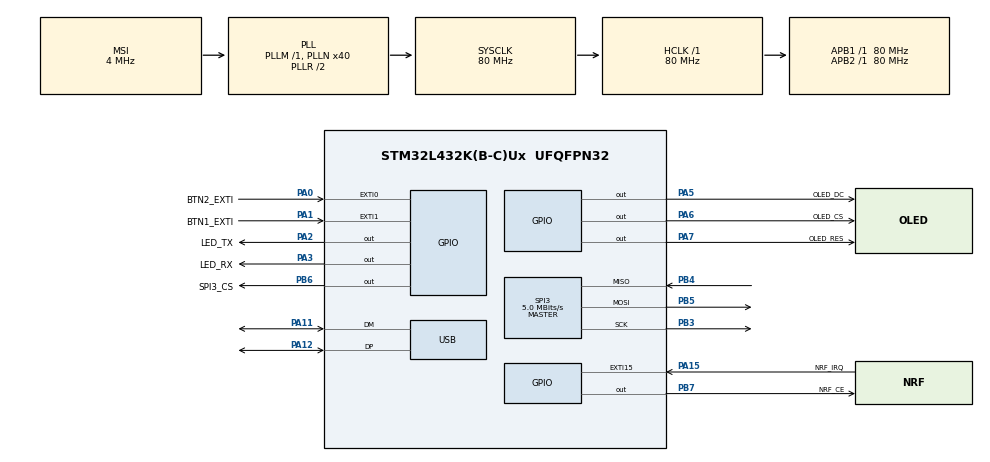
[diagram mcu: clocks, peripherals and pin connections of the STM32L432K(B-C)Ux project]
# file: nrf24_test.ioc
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Mcu.Family=STM32L4
Mcu.Name=STM32L432K(B-C)Ux
Mcu.Package=UFQFPN32
NVIC.EXTI15_10_IRQn=true\:0\:0\:false\:false\:true\:true\:true\:true
NVIC.PriorityGroup=NVIC_PRIORITYGROUP_4
NVIC.SPI3_IRQn=true\:0\:0\:false\:false\:true\:true\:true\:true
PA0.GPIO_Label=BTN2_EXTI
PA0.Signal=GPXTI0
PA1.GPIO_Label=BTN1_EXTI
PA1.Signal=GPXTI1
PA11.Mode=Device
PA11.Signal=USB_DM
PA12.Mode=Device
PA12.Signal=USB_DP
PA13\ (JTMS-SWDIO).Mode=Serial_Wire
PA13\ (JTMS-SWDIO).Signal=SYS_JTMS-SWDIO
PA14\ (JTCK-SWCLK).Mode=Serial_Wire
PA14\ (JTCK-SWCLK).Signal=SYS_JTCK-SWCLK
PA15\ (JTDI).GPIO_Label=NRF_IRQ
PA15\ (JTDI).Signal=GPXTI15
PA2.GPIO_Label=LED_TX
PA2.Signal=GPIO_Output
PA3.GPIO_Label=LED_RX
PA3.Signal=GPIO_Output
PA5.GPIO_Label=OLED_DC
PA5.Signal=GPIO_Output
PA6.GPIO_Label=OLED_CS
PA6.Signal=GPIO_Output
PA7.GPIO_Label=OLED_RES
PA7.Signal=GPIO_Output
PB3\ (JTDO-TRACESWO).Mode=Full_Duplex_Master
PB3\ (JTDO-TRACESWO).Signal=SPI3_SCK
PB4\ (NJTRST).Mode=Full_Duplex_Master
PB4\ (NJTRST).Signal=SPI3_MISO
PB5.Mode=Full_Duplex_Master
PB5.Signal=SPI3_MOSI
PB6.GPIO_Label=SPI3_CS
PB6.PinState=GPIO_PIN_SET
PB6.Signal=GPIO_Output
PB7.GPIO_Label=NRF_CE
PB7.Signal=GPIO_Output
ProjectManager.HeapSize=0x200
ProjectManager.StackSize=0x400
ProjectManager.TargetToolchain=STM32CubeIDE
RCC.ADCFreq_Value=48000000
RCC.AHBFreq_Value=80000000
RCC.APB1Freq_Value=80000000
RCC.APB1TimFreq_Value=80000000
RCC.APB2Freq_Value=80000000
RCC.APB2TimFreq_Value=80000000
RCC.CortexFreq_Value=80000000
RCC.HCLKFreq_Value=80000000
RCC.HSE_VALUE=8000000
RCC.HSI48_VALUE=48000000
RCC.HSI_VALUE=16000000
RCC.LSE_VALUE=32768
RCC.MSI_VALUE=4000000
RCC.PLLN=40
RCC.PLLSAI1N=24
RCC.SYSCLKFreq_VALUE=80000000
RCC.SYSCLKSource=RCC_SYSCLKSOURCE_PLLCLK
RCC.USBFreq_Value=48000000
RCC.VCOOutputFreq_Value=160000000
SPI3.BaudRatePrescaler=SPI_BAUDRATEPRESCALER_16
SPI3.CalculateBaudRate=5.0 MBits/s
SPI3.DataSize=SPI_DATASIZE_8BIT
SPI3.Direction=SPI_DIRECTION_2LINES
SPI3.Mode=SPI_MODE_MASTER
SPI3.VirtualType=VM_MASTER
VP_RCC_USB.Mode=CRS SYNC Source USB
board=custom

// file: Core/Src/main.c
/* USER CODE BEGIN Header */
/**
  ******************************************************************************
  * @file           : main.c
  * @brief          : Main program body
  ******************************************************************************
  * @attention
  *
  * Copyright (c) 2025 STMicroelectronics.
  * All rights reserved.
  *
  * This software is licensed under terms that can be found in the LICENSE file
  * in the root directory of this software component.
  * If no LICENSE file comes with this software, it is provided AS-IS.
  *
  ******************************************************************************
  */
/* USER CODE END Header */
#include "main.h"

/* USER CODE BEGIN PD */
#define NRF24_CMD_R_REGISTER 	0x00U
#define NRF24_REG_STATUS 		0x07U

/* USER CODE END PD */

SPI_HandleTypeDef hspi3;

PCD_HandleTypeDef hpcd_USB_FS;

void SystemClock_Config(void);
static void MX_GPIO_Init(void);
static void MX_SPI3_Init(void);
static void MX_USB_PCD_Init(void);
/* USER CODE BEGIN PFP */
uint8_t nrf24_read_register(uint8_t reg);
/* USER CODE END PFP */

int main(void)
{

  /* MCU Configuration--------------------------------------------------------*/

  /* Reset of all peripherals, Initializes the Flash interface and the Systick. */
  HAL_Init();

  /* Configure the system clock */
  SystemClock_Config();

  /* Initialize all configured peripherals */
  MX_GPIO_Init();
  MX_SPI3_Init();
  MX_USB_PCD_Init();
  /* USER CODE BEGIN 2 */
  uint8_t status = nrf24_read_register(NRF24_REG_STATUS);
  if (status != 0xFF && status != 0x00){
	  //succes
	  HAL_GPIO_WritePin(LED_RX_GPIO_Port, LED_RX_Pin, GPIO_PIN_SET);
	  HAL_GPIO_WritePin(LED_TX_GPIO_Port, LED_TX_Pin, GPIO_PIN_SET);
  }

  /* USER CODE END 2 */

  /* Infinite loop */
  while (1)
  {

  }
}

void SystemClock_Config(void)
{
  RCC_OscInitTypeDef RCC_OscInitStruct = {0};
  RCC_ClkInitTypeDef RCC_ClkInitStruct = {0};
  RCC_CRSInitTypeDef RCC_CRSInitStruct = {0};

  /** Configure the main internal regulator output voltage
  */
  if (HAL_PWREx_ControlVoltageScaling(PWR_REGULATOR_VOLTAGE_SCALE1) != HAL_OK)
  {
    Error_Handler();
  }

  /** Initializes the RCC Oscillators according to the specified parameters
  * in the RCC_OscInitTypeDef structure.
  */
  RCC_OscInitStruct.OscillatorType = RCC_OSCILLATORTYPE_MSI;
  RCC_OscInitStruct.MSIState = RCC_MSI_ON;
  RCC_OscInitStruct.MSICalibrationValue = 0;
  RCC_OscInitStruct.MSIClockRange = RCC_MSIRANGE_6;
  RCC_OscInitStruct.PLL.PLLState = RCC_PLL_ON;
  RCC_OscInitStruct.PLL.PLLSource = RCC_PLLSOURCE_MSI;
  RCC_OscInitStruct.PLL.PLLM = 1;
  RCC_OscInitStruct.PLL.PLLN = 40;
  RCC_OscInitStruct.PLL.PLLP = RCC_PLLP_DIV7;
  RCC_OscInitStruct.PLL.PLLQ = RCC_PLLQ_DIV2;
  RCC_OscInitStruct.PLL.PLLR = RCC_PLLR_DIV2;
  if (HAL_RCC_OscConfig(&RCC_OscInitStruct) != HAL_OK)
  {
    Error_Handler();
  }

  /** Initializes the CPU, AHB and APB buses clocks
  */
  RCC_ClkInitStruct.ClockType = RCC_CLOCKTYPE_HCLK|RCC_CLOCKTYPE_SYSCLK
                              |RCC_CLOCKTYPE_PCLK1|RCC_CLOCKTYPE_PCLK2;
  RCC_ClkInitStruct.SYSCLKSource = RCC_SYSCLKSOURCE_PLLCLK;
  RCC_ClkInitStruct.AHBCLKDivider = RCC_SYSCLK_DIV1;
  RCC_ClkInitStruct.APB1CLKDivider = RCC_HCLK_DIV1;
  RCC_ClkInitStruct.APB2CLKDivider = RCC_HCLK_DIV1;

  if (HAL_RCC_ClockConfig(&RCC_ClkInitStruct, FLASH_LATENCY_4) != HAL_OK)
  {
    Error_Handler();
  }

  /** Enable the SYSCFG APB clock
  */
  __HAL_RCC_CRS_CLK_ENABLE();

  /** Configures CRS
  */
  RCC_CRSInitStruct.Prescaler = RCC_CRS_SYNC_DIV1;
  RCC_CRSInitStruct.Source = RCC_CRS_SYNC_SOURCE_USB;
  RCC_CRSInitStruct.Polarity = RCC_CRS_SYNC_POLARITY_RISING;
  RCC_CRSInitStruct.ReloadValue = __HAL_RCC_CRS_RELOADVALUE_CALCULATE(48000000,1000);
  RCC_CRSInitStruct.ErrorLimitValue = 34;
  RCC_CRSInitStruct.HSI48CalibrationValue = 32;

  HAL_RCCEx_CRSConfig(&RCC_CRSInitStruct);
}

static void MX_SPI3_Init(void)
{

  /* SPI3 parameter configuration*/
  hspi3.Instance = SPI3;
  hspi3.Init.Mode = SPI_MODE_MASTER;
  hspi3.Init.Direction = SPI_DIRECTION_2LINES;
  hspi3.Init.DataSize = SPI_DATASIZE_8BIT;
  hspi3.Init.CLKPolarity = SPI_POLARITY_LOW;
  hspi3.Init.CLKPhase = SPI_PHASE_1EDGE;
  hspi3.Init.NSS = SPI_NSS_SOFT;
  hspi3.Init.BaudRatePrescaler = SPI_BAUDRATEPRESCALER_16;
  hspi3.Init.FirstBit = SPI_FIRSTBIT_MSB;
  hspi3.Init.TIMode = SPI_TIMODE_DISABLE;
  hspi3.Init.CRCCalculation = SPI_CRCCALCULATION_DISABLE;
  hspi3.Init.CRCPolynomial = 7;
  hspi3.Init.CRCLength = SPI_CRC_LENGTH_DATASIZE;
  hspi3.Init.NSSPMode = SPI_NSS_PULSE_ENABLE;
  if (HAL_SPI_Init(&hspi3) != HAL_OK)
  {
    Error_Handler();
  }

}

static void MX_USB_PCD_Init(void)
{

  hpcd_USB_FS.Instance = USB;
  hpcd_USB_FS.Init.dev_endpoints = 8;
  hpcd_USB_FS.Init.speed = PCD_SPEED_FULL;
  hpcd_USB_FS.Init.phy_itface = PCD_PHY_EMBEDDED;
  hpcd_USB_FS.Init.Sof_enable = DISABLE;
  hpcd_USB_FS.Init.low_power_enable = DISABLE;
  hpcd_USB_FS.Init.lpm_enable = DISABLE;
  hpcd_USB_FS.Init.battery_charging_enable = DISABLE;
  if (HAL_PCD_Init(&hpcd_USB_FS) != HAL_OK)
  {
    Error_Handler();
  }

}

static void MX_GPIO_Init(void)
{
  GPIO_InitTypeDef GPIO_InitStruct = {0};

  /* GPIO Ports Clock Enable */
  __HAL_RCC_GPIOA_CLK_ENABLE();
  __HAL_RCC_GPIOB_CLK_ENABLE();

  /*Configure GPIO pin Output Level */
  HAL_GPIO_WritePin(GPIOA, LED_TX_Pin|LED_RX_Pin|OLED_DC_Pin|OLED_CS_Pin
                          |OLED_RES_Pin, GPIO_PIN_RESET);

  /*Configure GPIO pin Output Level */
  HAL_GPIO_WritePin(SPI3_CS_GPIO_Port, SPI3_CS_Pin, GPIO_PIN_SET);

  /*Configure GPIO pin Output Level */
  HAL_GPIO_WritePin(NRF_CE_GPIO_Port, NRF_CE_Pin, GPIO_PIN_RESET);

  /*Configure GPIO pins : BTN2_EXTI_Pin BTN1_EXTI_Pin NRF_IRQ_Pin */
  GPIO_InitStruct.Pin = BTN2_EXTI_Pin|BTN1_EXTI_Pin|NRF_IRQ_Pin;
  GPIO_InitStruct.Mode = GPIO_MODE_IT_RISING;
  GPIO_InitStruct.Pull = GPIO_NOPULL;
  HAL_GPIO_Init(GPIOA, &GPIO_InitStruct);

  /*Configure GPIO pins : LED_TX_Pin LED_RX_Pin OLED_DC_Pin OLED_CS_Pin
                           OLED_RES_Pin */
  GPIO_InitStruct.Pin = LED_TX_Pin|LED_RX_Pin|OLED_DC_Pin|OLED_CS_Pin
                          |OLED_RES_Pin;
  GPIO_InitStruct.Mode = GPIO_MODE_OUTPUT_PP;
  GPIO_InitStruct.Pull = GPIO_NOPULL;
  GPIO_InitStruct.Speed = GPIO_SPEED_FREQ_LOW;
  HAL_GPIO_Init(GPIOA, &GPIO_InitStruct);

  /*Configure GPIO pins : SPI3_CS_Pin NRF_CE_Pin */
  GPIO_InitStruct.Pin = SPI3_CS_Pin|NRF_CE_Pin;
  GPIO_InitStruct.Mode = GPIO_MODE_OUTPUT_PP;
  GPIO_InitStruct.Pull = GPIO_NOPULL;
  GPIO_InitStruct.Speed = GPIO_SPEED_FREQ_LOW;
  HAL_GPIO_Init(GPIOB, &GPIO_InitStruct);

  /* EXTI interrupt init*/
  HAL_NVIC_SetPriority(EXTI15_10_IRQn, 0, 0);
  HAL_NVIC_EnableIRQ(EXTI15_10_IRQn);

}

/* USER CODE BEGIN 4 */
uint8_t nrf24_read_register(uint8_t reg){
	uint8_t tx[] = {NRF24_CMD_R_REGISTER | (reg & 0x1F), 0xFF};
	uint8_t rx[2];

	HAL_GPIO_WritePin(SPI3_CS_GPIO_Port, SPI3_CS_Pin, GPIO_PIN_RESET);
	HAL_SPI_TransmitReceive(&hspi3, tx, rx, 2, HAL_MAX_DELAY);
	HAL_GPIO_WritePin(SPI3_CS_GPIO_Port, SPI3_CS_Pin, GPIO_PIN_SET);

	return rx[1];
}
/* USER CODE END 4 */

void Error_Handler(void)
{
  __disable_irq();
  while (1)
  {
  }
}
